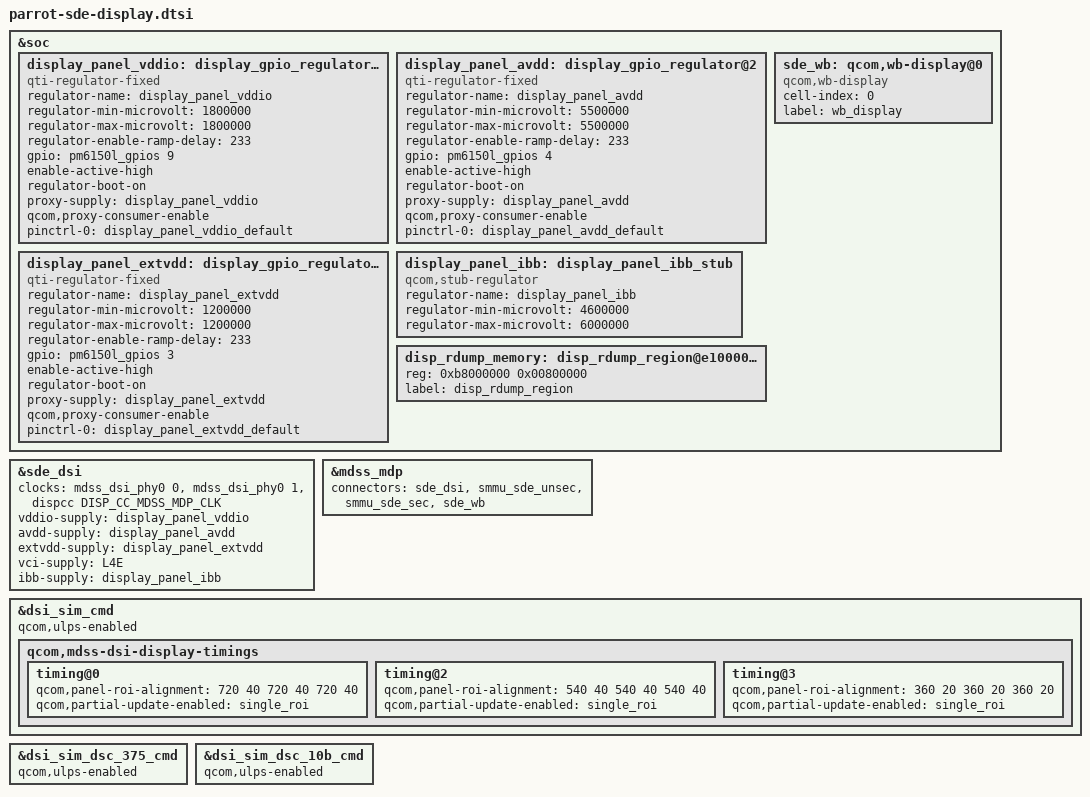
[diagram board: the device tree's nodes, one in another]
#include <dt-bindings/clock/qcom,dispcc-parrot.h>
#include "parrot-sde-display-common.dtsi"

&soc {
	display_panel_vddio: display_gpio_regulator@1 {
		compatible = "qti-regulator-fixed";
		regulator-name = "display_panel_vddio";
		regulator-min-microvolt = <1800000>;
		regulator-max-microvolt = <1800000>;
		regulator-enable-ramp-delay = <233>;
		gpio = <&pm6150l_gpios 9 0>;
		enable-active-high;
		regulator-boot-on;
		proxy-supply = <&display_panel_vddio>;
		qcom,proxy-consumer-enable;
		pinctrl-names = "default";
		pinctrl-0 = <&display_panel_vddio_default>;
	};

	display_panel_avdd: display_gpio_regulator@2 {
		compatible = "qti-regulator-fixed";
		regulator-name = "display_panel_avdd";
		regulator-min-microvolt = <5500000>;
		regulator-max-microvolt = <5500000>;
		regulator-enable-ramp-delay = <233>;
		gpio = <&pm6150l_gpios 4 0>;
		enable-active-high;
		regulator-boot-on;
		proxy-supply = <&display_panel_avdd>;
		qcom,proxy-consumer-enable;
		pinctrl-names = "default";
		pinctrl-0 = <&display_panel_avdd_default>;
	};

	display_panel_extvdd: display_gpio_regulator@3 {
		compatible = "qti-regulator-fixed";
		regulator-name = "display_panel_extvdd";
		regulator-min-microvolt = <1200000>;
		regulator-max-microvolt = <1200000>;
		regulator-enable-ramp-delay = <233>;
		gpio = <&pm6150l_gpios 3 0>;
		enable-active-high;
		regulator-boot-on;
		proxy-supply = <&display_panel_extvdd>;
		qcom,proxy-consumer-enable;
		pinctrl-names = "default";
		pinctrl-0 = <&display_panel_extvdd_default>;
	};

	display_panel_ibb: display_panel_ibb_stub {
		compatible = "qcom,stub-regulator";
		regulator-name = "display_panel_ibb";
		regulator-min-microvolt = <4600000>;
		regulator-max-microvolt = <6000000>;
	};

	sde_wb: qcom,wb-display@0 {
		compatible = "qcom,wb-display";
		cell-index = <0>;
		label = "wb_display";
	};

	disp_rdump_memory: disp_rdump_region@e1000000 {
		reg = <0xb8000000 0x00800000>;
		label = "disp_rdump_region";
	};
};

&sde_dsi {
	clocks = <&mdss_dsi_phy0 0>,
			<&mdss_dsi_phy0 1>,
			 /*
			  * Currently the dsi clock handles are under the dsi
			  * controller DT node. As soon as the controller probe
			  * finishes, the dispcc sync state can get called before
			  * the dsi_display probe potentially disturbing the clock
			  * votes for cont_splash use case. Hence we are no longer
			  * protected by the component model in this case against the
			  * disp cc sync state getting triggered after the dsi_ctrl
			  * probe. To protect against this incorrect sync state trigger
			  * add this dummy MDP clk vote handle to the dsi_display
			  * DT node. Since the dsi_display driver does not parse
			  * MDP clock nodes, no actual vote shall be added and this
			  * change is done just to satisfy sync state requirements.
			  */
			 <&dispcc DISP_CC_MDSS_MDP_CLK>;
	clock-names = "pll_byte_clk0", "pll_dsi_clk0",
			"mdp_core_clk";

	vddio-supply = <&display_panel_vddio>;
	avdd-supply = <&display_panel_avdd>;
	extvdd-supply = <&display_panel_extvdd>;
	vci-supply = <&L4E>;
	ibb-supply = <&display_panel_ibb>;
};

&mdss_mdp {
	connectors = <&sde_dsi &smmu_sde_unsec &smmu_sde_sec &sde_wb>;
};

&dsi_sim_cmd{
	qcom,ulps-enabled;
	qcom,mdss-dsi-display-timings {
		timing@0 { /* WQHD 60FPS cmd vid mode*/
			qcom,panel-roi-alignment = <720 40 720 40 720 40>;
			qcom,partial-update-enabled = "single_roi";
		};
		timing@2 { /* FHD 60FPS cmd mode*/
			qcom,panel-roi-alignment = <540 40 540 40 540 40>;
			qcom,partial-update-enabled = "single_roi";
		};
		timing@3 { /* HD 60FPS cmd mode*/
			qcom,panel-roi-alignment = <360 20 360 20 360 20>;
			qcom,partial-update-enabled = "single_roi";
		};
	};
};

&dsi_sim_dsc_375_cmd {
	qcom,ulps-enabled;
};

&dsi_sim_dsc_10b_cmd {
	qcom,ulps-enabled;
};
